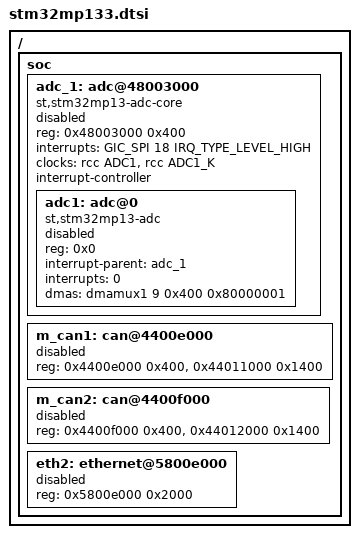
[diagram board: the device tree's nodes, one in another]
// SPDX-License-Identifier: (GPL-2.0+ OR BSD-3-Clause)
/*
 * Copyright (C) STMicroelectronics 2019 - All Rights Reserved
 * Author: Alexandre Torgue <alexandre.torgue@st.com> for STMicroelectronics.
 */

#include "stm32mp131.dtsi"

/ {
	soc {
		adc_1: adc@48003000 {
			compatible = "st,stm32mp13-adc-core";
			reg = <0x48003000 0x400>;
			interrupts = <GIC_SPI 18 IRQ_TYPE_LEVEL_HIGH>;
			clocks = <&rcc ADC1>, <&rcc ADC1_K>;
			clock-names = "bus", "adc";
			interrupt-controller;
			#interrupt-cells = <1>;
			#address-cells = <1>;
			#size-cells = <0>;
			status = "disabled";

			adc1: adc@0 {
				compatible = "st,stm32mp13-adc";
				#io-channel-cells = <1>;
				reg = <0x0>;
				interrupt-parent = <&adc_1>;
				interrupts = <0>;
				dmas = <&dmamux1 9 0x400 0x80000001>;
				dma-names = "rx";
				status = "disabled";
			};
		};

		m_can1: can@4400e000 {
			reg = <0x4400e000 0x400>, <0x44011000 0x1400>;
			status = "disabled";
		};

		m_can2: can@4400f000 {
			reg = <0x4400f000 0x400>, <0x44012000 0x1400>;
			status = "disabled";
		};

		eth2: ethernet@5800e000 {
			reg = <0x5800e000 0x2000>;
			status = "disabled";
		};
	};
};
